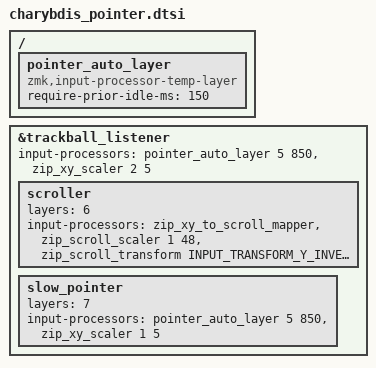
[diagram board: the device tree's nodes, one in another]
#include <input/processors.dtsi>
#include <dt-bindings/zmk/input_transform.h>

/ {
    pointer_auto_layer: pointer_auto_layer {
        compatible = "zmk,input-processor-temp-layer";
        #input-processor-cells = <2>;
        require-prior-idle-ms = <150>;
    };
};

&trackball_listener {
    input-processors = <
        &pointer_auto_layer 5 850
        &zip_xy_scaler 2 5
    >;
    scroller {
        layers = <6>;
        input-processors = <&zip_xy_to_scroll_mapper &zip_scroll_scaler 1 48 &zip_scroll_transform INPUT_TRANSFORM_Y_INVERT>;
    };
    slow_pointer {
        layers = <7>;
        input-processors = <
            &pointer_auto_layer 5 850
            &zip_xy_scaler 1 5
        >;
    };
};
